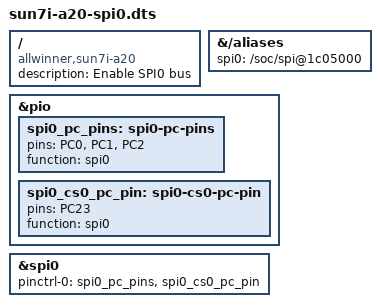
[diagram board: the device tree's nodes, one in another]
/dts-v1/;
/plugin/;

/ {
	compatible = "allwinner,sun7i-a20";
	description = "Enable SPI0 bus";

	fragment@0 {
		target-path = "/aliases";
		__overlay__ {
			spi0 = "/soc/spi@1c05000";
		};
	};

	fragment@1 {
		target = <&pio>;
		__overlay__ {
			spi0_pc_pins: spi0-pc-pins {
				pins = "PC0", "PC1", "PC2";
				function = "spi0";
			};

			spi0_cs0_pc_pin: spi0-cs0-pc-pin {
				pins = "PC23";
				function = "spi0";
			};
		};
	};

	fragment@2 {
		target = <&spi0>;
		__overlay__ {
			pinctrl-names = "default";
			pinctrl-0 = <&spi0_pc_pins>, <&spi0_cs0_pc_pin>;
			status = "okay";
		};
	};
};
